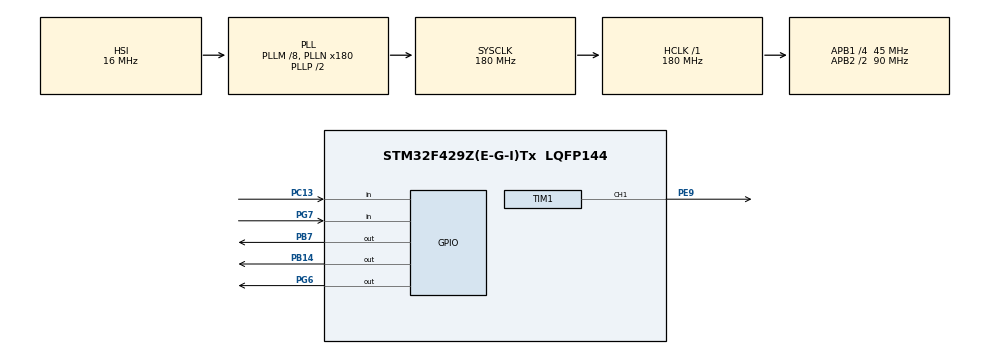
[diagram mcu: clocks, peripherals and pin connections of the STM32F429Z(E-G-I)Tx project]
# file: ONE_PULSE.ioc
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Mcu.Family=STM32F4
Mcu.Name=STM32F429Z(E-G-I)Tx
Mcu.Package=LQFP144
NVIC.PriorityGroup=NVIC_PRIORITYGROUP_4
PA1.GPIO_Mode=GPIO_MODE_AF_PP
PA1.GPIO_PuPd=GPIO_NOPULL
PA1.GPIO_Speed=GPIO_SPEED_FREQ_VERY_HIGH
PA1.Signal=ETH_REF_CLK
PA10.GPIO_Mode=GPIO_MODE_AF_PP
PA10.GPIO_PuPd=GPIO_NOPULL
PA10.GPIO_Speed=GPIO_SPEED_FREQ_VERY_HIGH
PA10.Signal=USB_OTG_FS_ID
PA11.GPIO_Mode=GPIO_MODE_AF_PP
PA11.GPIO_PuPd=GPIO_NOPULL
PA11.GPIO_Speed=GPIO_SPEED_FREQ_VERY_HIGH
PA11.Signal=USB_OTG_FS_DM
PA12.GPIO_Mode=GPIO_MODE_AF_PP
PA12.GPIO_PuPd=GPIO_NOPULL
PA12.GPIO_Speed=GPIO_SPEED_FREQ_VERY_HIGH
PA12.Signal=USB_OTG_FS_DP
PA13.Mode=Serial_Wire
PA13.Signal=SYS_JTMS-SWDIO
PA14.Mode=Serial_Wire
PA14.Signal=SYS_JTCK-SWCLK
PA2.GPIO_Mode=GPIO_MODE_AF_PP
PA2.GPIO_PuPd=GPIO_NOPULL
PA2.GPIO_Speed=GPIO_SPEED_FREQ_VERY_HIGH
PA2.Signal=ETH_MDIO
PA7.GPIO_Mode=GPIO_MODE_AF_PP
PA7.GPIO_PuPd=GPIO_NOPULL
PA7.GPIO_Speed=GPIO_SPEED_FREQ_VERY_HIGH
PA7.Signal=ETH_CRS_DV
PA8.GPIO_Mode=GPIO_MODE_AF_PP
PA8.GPIO_PuPd=GPIO_NOPULL
PA8.GPIO_Speed=GPIO_SPEED_FREQ_VERY_HIGH
PA8.Signal=USB_OTG_FS_SOF
PA9.GPIO_Mode=GPIO_MODE_INPUT
PA9.GPIO_PuPd=GPIO_NOPULL
PA9.Signal=USB_OTG_FS_VBUS
PB13.GPIO_Mode=GPIO_MODE_AF_PP
PB13.GPIO_PuPd=GPIO_NOPULL
PB13.GPIO_Speed=GPIO_SPEED_FREQ_VERY_HIGH
PB13.Signal=ETH_TXD1
PB14.GPIO_ModeDefaultOutputPP=GPIO_MODE_OUTPUT_PP
PB14.GPIO_PuPd=GPIO_NOPULL
PB14.GPIO_Speed=GPIO_SPEED_FREQ_LOW
PB14.PinState=GPIO_PIN_RESET
PB14.Signal=GPIO_Output
PB7.GPIO_ModeDefaultOutputPP=GPIO_MODE_OUTPUT_PP
PB7.GPIO_PuPd=GPIO_NOPULL
PB7.GPIO_Speed=GPIO_SPEED_FREQ_LOW
PB7.PinState=GPIO_PIN_RESET
PB7.Signal=GPIO_Output
PC1.GPIO_Mode=GPIO_MODE_AF_PP
PC1.GPIO_PuPd=GPIO_NOPULL
PC1.GPIO_Speed=GPIO_SPEED_FREQ_VERY_HIGH
PC1.Signal=ETH_MDC
PC13.GPIO_Mode=GPIO_MODE_INPUT
PC13.GPIO_PuPd=GPIO_NOPULL
PC13.Signal=GPIO_Input
PC14/OSC32_IN.Signal=RCC_OSC32_IN
PC15/OSC32_OUT.Signal=RCC_OSC32_OUT
PC4.GPIO_Mode=GPIO_MODE_AF_PP
PC4.GPIO_PuPd=GPIO_NOPULL
PC4.GPIO_Speed=GPIO_SPEED_FREQ_VERY_HIGH
PC4.Signal=ETH_RXD0
PC5.GPIO_Mode=GPIO_MODE_AF_PP
PC5.GPIO_PuPd=GPIO_NOPULL
PC5.GPIO_Speed=GPIO_SPEED_FREQ_VERY_HIGH
PC5.Signal=ETH_RXD1
PD8.GPIO_Mode=GPIO_MODE_AF_PP
PD8.GPIO_PuPd=GPIO_NOPULL
PD8.GPIO_Speed=GPIO_SPEED_FREQ_VERY_HIGH
PD8.Signal=USART3_TX
PD9.GPIO_Mode=GPIO_MODE_AF_PP
PD9.GPIO_PuPd=GPIO_NOPULL
PD9.GPIO_Speed=GPIO_SPEED_FREQ_VERY_HIGH
PD9.Signal=USART3_RX
PE9.Signal=S_TIM1_CH1
PG11.GPIO_Mode=GPIO_MODE_AF_PP
PG11.GPIO_PuPd=GPIO_NOPULL
PG11.GPIO_Speed=GPIO_SPEED_FREQ_VERY_HIGH
PG11.Signal=ETH_TX_EN
PG13.GPIO_Mode=GPIO_MODE_AF_PP
PG13.GPIO_PuPd=GPIO_NOPULL
PG13.GPIO_Speed=GPIO_SPEED_FREQ_VERY_HIGH
PG13.Signal=ETH_TXD0
PG6.GPIO_ModeDefaultOutputPP=GPIO_MODE_OUTPUT_PP
PG6.GPIO_PuPd=GPIO_NOPULL
PG6.GPIO_Speed=GPIO_SPEED_FREQ_LOW
PG6.PinState=GPIO_PIN_RESET
PG6.Signal=GPIO_Output
PG7.GPIO_Mode=GPIO_MODE_INPUT
PG7.GPIO_PuPd=GPIO_NOPULL
PG7.Signal=GPIO_Input
PH0/OSC_IN.Mode=HSE-External-Oscillator
PH0/OSC_IN.Signal=RCC_OSC_IN
PH1/OSC_OUT.Mode=HSE-External-Oscillator
PH1/OSC_OUT.Signal=RCC_OSC_OUT
ProjectManager.HeapSize=0x200
ProjectManager.StackSize=0x400
ProjectManager.TargetToolchain=MDK-ARM V5
RCC.48MHZClocksFreq_Value=90000000
RCC.AHBFreq_Value=180000000
RCC.APB1CLKDivider=RCC_HCLK_DIV4
RCC.APB1Freq_Value=45000000
RCC.APB1TimFreq_Value=90000000
RCC.APB2CLKDivider=RCC_HCLK_DIV2
RCC.APB2Freq_Value=90000000
RCC.APB2TimFreq_Value=180000000
RCC.CortexFreq_Value=180000000
RCC.HCLKFreq_Value=180000000
RCC.HSE_VALUE=8000000
RCC.HSI_VALUE=16000000
RCC.LSE_VALUE=32768
RCC.PLLM=8
RCC.PLLMUL=RCC_PLL_MUL9
RCC.PLLN=180
RCC.PRESCALERUSB=RCC_USBCLKSOURCE_PLL_DIV1_5
RCC.SYSCLKFreq_VALUE=180000000
RCC.SYSCLKSource=RCC_SYSCLKSOURCE_PLLCLK
RCC.SYSCLKSourceVirtual=RCC_SYSCLKSOURCE_PLLCLK
RCC.USBFreq_Value=48000000
RCC.VCOOutputFreq_Value=360000000
SH.S_TIM1_CH1.0=TIM1_CH1,PWM Generation1 CH1
TIM1.OCMode_PWM-PWM\ Generation1\ CH1=TIM_OCMODE_PWM2
TIM1.Period=450-1
TIM1.Prescaler=400-1
TIM1.Pulse-PWM\ Generation1\ CH1=225
TIM1.RepetitionCounter=100
TIM1.TIM_MasterOutputTrigger=TIM_TRGO_UPDATE
VP_TIM1_VS_ClockSourceINT.Mode=Internal
VP_TIM1_VS_OPM.Mode=OPM_bit
board=NUCLEO-F429ZI

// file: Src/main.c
/**
  ******************************************************************************
  * File Name          : main.c
  * Description        : Main program body
  ******************************************************************************
  *
  * COPYRIGHT(c) 2017 STMicroelectronics
  *
  * Redistribution and use in source and binary forms, with or without modification,
  * are permitted provided that the following conditions are met:
  *   1. Redistributions of source code must retain the above copyright notice,
  *      this list of conditions and the following disclaimer.
  *   2. Redistributions in binary form must reproduce the above copyright notice,
  *      this list of conditions and the following disclaimer in the documentation
  *      and/or other materials provided with the distribution.
  *   3. Neither the name of STMicroelectronics nor the names of its contributors
  *      may be used to endorse or promote products derived from this software
  *      without specific prior written permission.
  *
  * THIS SOFTWARE IS PROVIDED BY THE COPYRIGHT HOLDERS AND CONTRIBUTORS "AS IS"
  * AND ANY EXPRESS OR IMPLIED WARRANTIES, INCLUDING, BUT NOT LIMITED TO, THE
  * IMPLIED WARRANTIES OF MERCHANTABILITY AND FITNESS FOR A PARTICULAR PURPOSE ARE
  * DISCLAIMED. IN NO EVENT SHALL THE COPYRIGHT HOLDER OR CONTRIBUTORS BE LIABLE
  * FOR ANY DIRECT, INDIRECT, INCIDENTAL, SPECIAL, EXEMPLARY, OR CONSEQUENTIAL
  * DAMAGES (INCLUDING, BUT NOT LIMITED TO, PROCUREMENT OF SUBSTITUTE GOODS OR
  * SERVICES; LOSS OF USE, DATA, OR PROFITS; OR BUSINESS INTERRUPTION) HOWEVER
  * CAUSED AND ON ANY THEORY OF LIABILITY, WHETHER IN CONTRACT, STRICT LIABILITY,
  * OR TORT (INCLUDING NEGLIGENCE OR OTHERWISE) ARISING IN ANY WAY OUT OF THE USE
  * OF THIS SOFTWARE, EVEN IF ADVISED OF THE POSSIBILITY OF SUCH DAMAGE.
  *
  ******************************************************************************
  */
#include "main.h"
#include "stm32f4xx_hal.h"

TIM_HandleTypeDef htim1;

/* USER CODE BEGIN PV */
/* Private variables ---------------------------------------------------------*/

/* USER CODE END PV */

void SystemClock_Config(void);
void Error_Handler(void);
static void MX_GPIO_Init(void);
static void MX_TIM1_Init(void);
void HAL_TIM_MspPostInit(TIM_HandleTypeDef *htim);

/* USER CODE BEGIN PFP */
/* Private function prototypes -----------------------------------------------*/

/* USER CODE END PFP */

int main(void)
{

  /* MCU Configuration----------------------------------------------------------*/

  /* Reset of all peripherals, Initializes the Flash interface and the Systick. */
  HAL_Init();

  /* Configure the system clock */
  SystemClock_Config();

  /* Initialize all configured peripherals */
  MX_GPIO_Init();
  MX_TIM1_Init();

  /* USER CODE BEGIN 2 */
	if (HAL_TIM_PWM_Start(&htim1, TIM_CHANNEL_1) == HAL_OK)
	{
		printf("One Pulse Done");
	}
	//HAL_TIM_PWM_Start(&htim1, TIM_CHANNEL_1); // Same effect
	/*__HAL_TIM_ENABLE(&htim1);
	if (HAL_TIM_OnePulse_Start(&htim1, TIM_CHANNEL_1) != HAL_OK)
  {
    Error_Handler();
  } */
  /* USER CODE END 2 */

  /* Infinite loop */
  while (1)
  {

  /* USER CODE BEGIN 3 */
		/*__HAL_TIM_ENABLE(&htim1);
		__HAL_TIM_SetCounter(&htim1, 0);
		HAL_TIM_OnePulse_Start(&htim1, TIM_CHANNEL_1);
		HAL_Delay(1);
		HAL_TIM_OnePulse_Stop(&htim1, TIM_CHANNEL_1);*/
  }
  /* USER CODE END 3 */

}

/** System Clock Configuration
*/
void SystemClock_Config(void)
{

  RCC_OscInitTypeDef RCC_OscInitStruct;
  RCC_ClkInitTypeDef RCC_ClkInitStruct;

    /**Configure the main internal regulator output voltage
    */
  __HAL_RCC_PWR_CLK_ENABLE();

  __HAL_PWR_VOLTAGESCALING_CONFIG(PWR_REGULATOR_VOLTAGE_SCALE1);

    /**Initializes the CPU, AHB and APB busses clocks
    */
  RCC_OscInitStruct.OscillatorType = RCC_OSCILLATORTYPE_HSI;
  RCC_OscInitStruct.HSIState = RCC_HSI_ON;
  RCC_OscInitStruct.HSICalibrationValue = 16;
  RCC_OscInitStruct.PLL.PLLState = RCC_PLL_ON;
  RCC_OscInitStruct.PLL.PLLSource = RCC_PLLSOURCE_HSI;
  RCC_OscInitStruct.PLL.PLLM = 8;
  RCC_OscInitStruct.PLL.PLLN = 180;
  RCC_OscInitStruct.PLL.PLLP = RCC_PLLP_DIV2;
  RCC_OscInitStruct.PLL.PLLQ = 4;
  if (HAL_RCC_OscConfig(&RCC_OscInitStruct) != HAL_OK)
  {
    Error_Handler();
  }

    /**Activate the Over-Drive mode
    */
  if (HAL_PWREx_EnableOverDrive() != HAL_OK)
  {
    Error_Handler();
  }

    /**Initializes the CPU, AHB and APB busses clocks
    */
  RCC_ClkInitStruct.ClockType = RCC_CLOCKTYPE_HCLK|RCC_CLOCKTYPE_SYSCLK
                              |RCC_CLOCKTYPE_PCLK1|RCC_CLOCKTYPE_PCLK2;
  RCC_ClkInitStruct.SYSCLKSource = RCC_SYSCLKSOURCE_PLLCLK;
  RCC_ClkInitStruct.AHBCLKDivider = RCC_SYSCLK_DIV1;
  RCC_ClkInitStruct.APB1CLKDivider = RCC_HCLK_DIV4;
  RCC_ClkInitStruct.APB2CLKDivider = RCC_HCLK_DIV2;

  if (HAL_RCC_ClockConfig(&RCC_ClkInitStruct, FLASH_LATENCY_5) != HAL_OK)
  {
    Error_Handler();
  }

    /**Configure the Systick interrupt time
    */
  HAL_SYSTICK_Config(HAL_RCC_GetHCLKFreq()/1000);

    /**Configure the Systick
    */
  HAL_SYSTICK_CLKSourceConfig(SYSTICK_CLKSOURCE_HCLK);

  /* SysTick_IRQn interrupt configuration */
  HAL_NVIC_SetPriority(SysTick_IRQn, 0, 0);
}

/* TIM1 init function */
static void MX_TIM1_Init(void)
{

  TIM_ClockConfigTypeDef sClockSourceConfig;
  TIM_MasterConfigTypeDef sMasterConfig;
  TIM_OC_InitTypeDef sConfigOC;
  TIM_BreakDeadTimeConfigTypeDef sBreakDeadTimeConfig;

  htim1.Instance = TIM1;
  htim1.Init.Prescaler = 4000-1;
  htim1.Init.CounterMode = TIM_COUNTERMODE_UP;
  htim1.Init.Period = 450-1;
  htim1.Init.ClockDivision = TIM_CLOCKDIVISION_DIV1;
  htim1.Init.RepetitionCounter = 200;
  if (HAL_TIM_Base_Init(&htim1) != HAL_OK)
  {
    Error_Handler();
  }

  sClockSourceConfig.ClockSource = TIM_CLOCKSOURCE_INTERNAL;
  if (HAL_TIM_ConfigClockSource(&htim1, &sClockSourceConfig) != HAL_OK)
  {
    Error_Handler();
  }

  if (HAL_TIM_PWM_Init(&htim1) != HAL_OK)
  {
    Error_Handler();
  }

  if (HAL_TIM_OnePulse_Init(&htim1, TIM_OPMODE_SINGLE) != HAL_OK)
  {
    Error_Handler();
  }

  sMasterConfig.MasterOutputTrigger = TIM_TRGO_UPDATE;
  sMasterConfig.MasterSlaveMode = TIM_MASTERSLAVEMODE_DISABLE;
  if (HAL_TIMEx_MasterConfigSynchronization(&htim1, &sMasterConfig) != HAL_OK)
  {
    Error_Handler();
  }

  sConfigOC.OCMode = TIM_OCMODE_PWM2;
  sConfigOC.Pulse = 225;
  sConfigOC.OCPolarity = TIM_OCPOLARITY_HIGH;
  sConfigOC.OCNPolarity = TIM_OCNPOLARITY_HIGH;
  sConfigOC.OCFastMode = TIM_OCFAST_DISABLE;
  sConfigOC.OCIdleState = TIM_OCIDLESTATE_RESET;
  sConfigOC.OCNIdleState = TIM_OCNIDLESTATE_RESET;
  if (HAL_TIM_PWM_ConfigChannel(&htim1, &sConfigOC, TIM_CHANNEL_1) != HAL_OK)
  {
    Error_Handler();
  }

  sBreakDeadTimeConfig.OffStateRunMode = TIM_OSSR_DISABLE;
  sBreakDeadTimeConfig.OffStateIDLEMode = TIM_OSSI_DISABLE;
  sBreakDeadTimeConfig.LockLevel = TIM_LOCKLEVEL_OFF;
  sBreakDeadTimeConfig.DeadTime = 0;
  sBreakDeadTimeConfig.BreakState = TIM_BREAK_DISABLE;
  sBreakDeadTimeConfig.BreakPolarity = TIM_BREAKPOLARITY_HIGH;
  sBreakDeadTimeConfig.AutomaticOutput = TIM_AUTOMATICOUTPUT_DISABLE;
  if (HAL_TIMEx_ConfigBreakDeadTime(&htim1, &sBreakDeadTimeConfig) != HAL_OK)
  {
    Error_Handler();
  }

  HAL_TIM_MspPostInit(&htim1);

}

/** Configure pins as
        * Analog
        * Input
        * Output
        * EVENT_OUT
        * EXTI
     PC1   ------> ETH_MDC
     PA1   ------> ETH_REF_CLK
     PA2   ------> ETH_MDIO
     PA7   ------> ETH_CRS_DV
     PC4   ------> ETH_RXD0
     PC5   ------> ETH_RXD1
     PB13   ------> ETH_TXD1
     PD8   ------> USART3_TX
     PD9   ------> USART3_RX
     PA8   ------> USB_OTG_FS_SOF
     PA9   ------> USB_OTG_FS_VBUS
     PA10   ------> USB_OTG_FS_ID
     PA11   ------> USB_OTG_FS_DM
     PA12   ------> USB_OTG_FS_DP
     PG11   ------> ETH_TX_EN
     PG13   ------> ETH_TXD0
*/
static void MX_GPIO_Init(void)
{

  GPIO_InitTypeDef GPIO_InitStruct;

  /* GPIO Ports Clock Enable */
  __HAL_RCC_GPIOC_CLK_ENABLE();
  __HAL_RCC_GPIOH_CLK_ENABLE();
  __HAL_RCC_GPIOA_CLK_ENABLE();
  __HAL_RCC_GPIOE_CLK_ENABLE();
  __HAL_RCC_GPIOB_CLK_ENABLE();
  __HAL_RCC_GPIOD_CLK_ENABLE();
  __HAL_RCC_GPIOG_CLK_ENABLE();

  /*Configure GPIO pin : PC13 */
  GPIO_InitStruct.Pin = GPIO_PIN_13;
  GPIO_InitStruct.Mode = GPIO_MODE_INPUT;
  GPIO_InitStruct.Pull = GPIO_NOPULL;
  HAL_GPIO_Init(GPIOC, &GPIO_InitStruct);

  /*Configure GPIO pins : PC1 PC4 PC5 */
  GPIO_InitStruct.Pin = GPIO_PIN_1|GPIO_PIN_4|GPIO_PIN_5;
  GPIO_InitStruct.Mode = GPIO_MODE_AF_PP;
  GPIO_InitStruct.Pull = GPIO_NOPULL;
  GPIO_InitStruct.Speed = GPIO_SPEED_FREQ_VERY_HIGH;
  GPIO_InitStruct.Alternate = GPIO_AF11_ETH;
  HAL_GPIO_Init(GPIOC, &GPIO_InitStruct);

  /*Configure GPIO pins : PA1 PA2 PA7 */
  GPIO_InitStruct.Pin = GPIO_PIN_1|GPIO_PIN_2|GPIO_PIN_7;
  GPIO_InitStruct.Mode = GPIO_MODE_AF_PP;
  GPIO_InitStruct.Pull = GPIO_NOPULL;
  GPIO_InitStruct.Speed = GPIO_SPEED_FREQ_VERY_HIGH;
  GPIO_InitStruct.Alternate = GPIO_AF11_ETH;
  HAL_GPIO_Init(GPIOA, &GPIO_InitStruct);

  /*Configure GPIO pin : PB13 */
  GPIO_InitStruct.Pin = GPIO_PIN_13;
  GPIO_InitStruct.Mode = GPIO_MODE_AF_PP;
  GPIO_InitStruct.Pull = GPIO_NOPULL;
  GPIO_InitStruct.Speed = GPIO_SPEED_FREQ_VERY_HIGH;
  GPIO_InitStruct.Alternate = GPIO_AF11_ETH;
  HAL_GPIO_Init(GPIOB, &GPIO_InitStruct);

  /*Configure GPIO pins : PB14 PB7 */
  GPIO_InitStruct.Pin = GPIO_PIN_14|GPIO_PIN_7;
  GPIO_InitStruct.Mode = GPIO_MODE_OUTPUT_PP;
  GPIO_InitStruct.Pull = GPIO_NOPULL;
  GPIO_InitStruct.Speed = GPIO_SPEED_FREQ_LOW;
  HAL_GPIO_Init(GPIOB, &GPIO_InitStruct);

  /*Configure GPIO pins : PD8 PD9 */
  GPIO_InitStruct.Pin = GPIO_PIN_8|GPIO_PIN_9;
  GPIO_InitStruct.Mode = GPIO_MODE_AF_PP;
  GPIO_InitStruct.Pull = GPIO_NOPULL;
  GPIO_InitStruct.Speed = GPIO_SPEED_FREQ_VERY_HIGH;
  GPIO_InitStruct.Alternate = GPIO_AF7_USART3;
  HAL_GPIO_Init(GPIOD, &GPIO_InitStruct);

  /*Configure GPIO pin : PG6 */
  GPIO_InitStruct.Pin = GPIO_PIN_6;
  GPIO_InitStruct.Mode = GPIO_MODE_OUTPUT_PP;
  GPIO_InitStruct.Pull = GPIO_NOPULL;
  GPIO_InitStruct.Speed = GPIO_SPEED_FREQ_LOW;
  HAL_GPIO_Init(GPIOG, &GPIO_InitStruct);

  /*Configure GPIO pin : PG7 */
  GPIO_InitStruct.Pin = GPIO_PIN_7;
  GPIO_InitStruct.Mode = GPIO_MODE_INPUT;
  GPIO_InitStruct.Pull = GPIO_NOPULL;
  HAL_GPIO_Init(GPIOG, &GPIO_InitStruct);

  /*Configure GPIO pins : PA8 PA10 PA11 PA12 */
  GPIO_InitStruct.Pin = GPIO_PIN_8|GPIO_PIN_10|GPIO_PIN_11|GPIO_PIN_12;
  GPIO_InitStruct.Mode = GPIO_MODE_AF_PP;
  GPIO_InitStruct.Pull = GPIO_NOPULL;
  GPIO_InitStruct.Speed = GPIO_SPEED_FREQ_VERY_HIGH;
  GPIO_InitStruct.Alternate = GPIO_AF10_OTG_FS;
  HAL_GPIO_Init(GPIOA, &GPIO_InitStruct);

  /*Configure GPIO pin : PA9 */
  GPIO_InitStruct.Pin = GPIO_PIN_9;
  GPIO_InitStruct.Mode = GPIO_MODE_INPUT;
  GPIO_InitStruct.Pull = GPIO_NOPULL;
  HAL_GPIO_Init(GPIOA, &GPIO_InitStruct);

  /*Configure GPIO pins : PG11 PG13 */
  GPIO_InitStruct.Pin = GPIO_PIN_11|GPIO_PIN_13;
  GPIO_InitStruct.Mode = GPIO_MODE_AF_PP;
  GPIO_InitStruct.Pull = GPIO_NOPULL;
  GPIO_InitStruct.Speed = GPIO_SPEED_FREQ_VERY_HIGH;
  GPIO_InitStruct.Alternate = GPIO_AF11_ETH;
  HAL_GPIO_Init(GPIOG, &GPIO_InitStruct);

  /*Configure GPIO pin Output Level */
  HAL_GPIO_WritePin(GPIOB, GPIO_PIN_14|GPIO_PIN_7, GPIO_PIN_RESET);

  /*Configure GPIO pin Output Level */
  HAL_GPIO_WritePin(GPIOG, GPIO_PIN_6, GPIO_PIN_RESET);

}

void Error_Handler(void)
{
  while(1)
  {
  }
}

/************************ (C) COPYRIGHT STMicroelectronics *****END OF FILE****/
